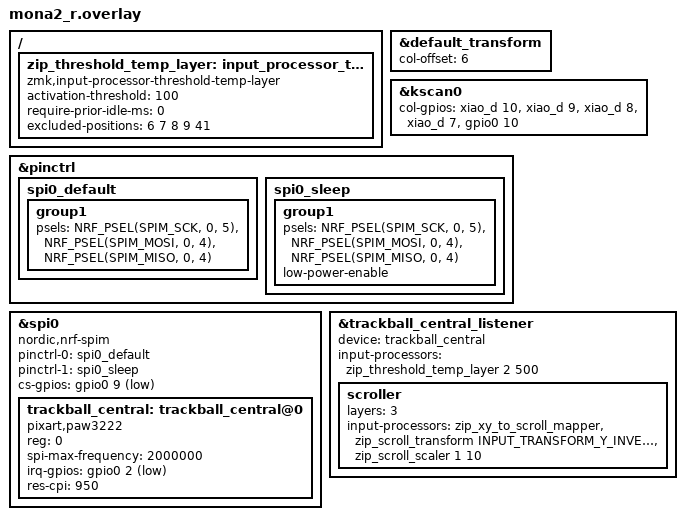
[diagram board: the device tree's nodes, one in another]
#include "mona2.dtsi"
#include <input/processors.dtsi>
#include <zephyr/dt-bindings/input/input-event-codes.h>

/ {
    // カスタム入力プロセッサー: 閾値付き一時レイヤー
    zip_threshold_temp_layer: input_processor_threshold_temp_layer {
        compatible = "zmk,input-processor-threshold-temp-layer";
        #input-processor-cells = <2>;
        activation-threshold = <100>;
        require-prior-idle-ms = <0>;
    require-prior-idle-ms = <0>;
    excluded-positions = <6 7 8 9 41>;   // Left/Mid/Right Click + Scroll 토글 키 2개
    };
};

&default_transform {
    col-offset = <6>;
};

&kscan0 {
        col-gpios
            = <&xiao_d 10 GPIO_ACTIVE_HIGH>
            , <&xiao_d 9 GPIO_ACTIVE_HIGH> 
            , <&xiao_d 8 GPIO_ACTIVE_HIGH> 
            , <&xiao_d 7 GPIO_ACTIVE_HIGH> 
            , <&gpio0 10 GPIO_ACTIVE_HIGH>
            ;
};

&pinctrl {
    spi0_default: spi0_default {
        group1 {
            psels = <NRF_PSEL(SPIM_SCK, 0, 5)>,
                <NRF_PSEL(SPIM_MOSI, 0, 4)>,
                <NRF_PSEL(SPIM_MISO, 0, 4)>;
        };
    };

    spi0_sleep: spi0_sleep {
        group1 {
            psels = <NRF_PSEL(SPIM_SCK, 0, 5)>,
                <NRF_PSEL(SPIM_MOSI, 0, 4)>,
                <NRF_PSEL(SPIM_MISO, 0, 4)>;
            low-power-enable;
        };
    };
};

&spi0 {
    status = "okay";
    compatible = "nordic,nrf-spim";
    pinctrl-0 = <&spi0_default>;
    pinctrl-1 = <&spi0_sleep>;
    pinctrl-names = "default", "sleep";
    cs-gpios = <&gpio0 9 GPIO_ACTIVE_LOW>;

    trackball_central: trackball_central@0 {
        status = "okay";
        compatible = "pixart,paw3222";
        reg = <0>;
        spi-max-frequency = <2000000>;
        irq-gpios = <&gpio0 2 (GPIO_ACTIVE_LOW | GPIO_PULL_UP)>;
        res-cpi = <950>;
    };
};

// Overrides for the input listener node
&trackball_central_listener {
    status = "okay";
    device = <&trackball_central>;

    input-processors = <&zip_threshold_temp_layer 2 500>;

    scroller {
        layers = <3>;
        input-processors = <&zip_xy_to_scroll_mapper>,
                           <&zip_scroll_transform INPUT_TRANSFORM_Y_INVERT>,
                           <&zip_scroll_scaler 1 10>;
    };
};
